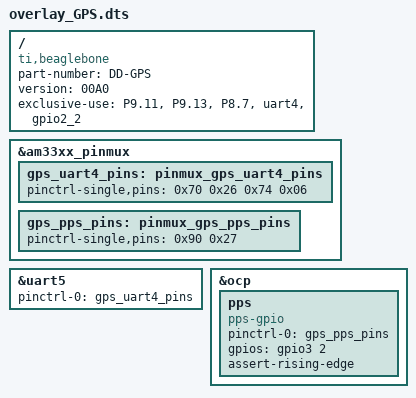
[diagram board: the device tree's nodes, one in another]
/*
 * Copyright (C) 2013 the8thlayerof.net
 *
 * GPS cape for UART4 on connector pins P9.11 P9.13 P8.7
 *
 * This program is free software; you can redistribute it and/or modify
 * it under the terms of the GNU General Public License version 2 as
 * published by the Free Software Foundation.
 */
/dts-v1/;
/plugin/;

/ {
        compatible = "ti,beaglebone", "ti,beaglebone-black";

        /* identification */
        part-number = "DD-GPS";
        version = "00A0";

        /* state the resources this cape uses */
        exclusive-use =
                /* the pin header uses */
                "P9.11",        /* uart4_rxd */
                "P9.13",        /* uart4_txd */
                "P8.7",        /* timer4/GPIO_66   */
                /* the hardware ip uses */
                "uart4", /* 0-based counting */
                "gpio2_2"; /* 0-based counting */

        fragment@0 {
                target = <&am33xx_pinmux>;
                __overlay__ {
                        gps_uart4_pins: pinmux_gps_uart4_pins {
                                pinctrl-single,pins = <
                                        0x70 0x26 /* P9.11 uart4_rxd MODE6 INPUT (RX) */
                                        0x74 0x06 /* P9.13 uart4_txd MODE6 OUTPUT (TX) */
                                >;
                        };

                        gps_pps_pins: pinmux_gps_pps_pins {
                                pinctrl-single,pins = <
                                      0x90 0x27 /* P8.7 gpio2_2 */
                                >;
                        };

                };
        };

        fragment@1 {
                target = <&uart5>;      /* 1-based counting */
                __overlay__ {
                        status = "okay";
                        pinctrl-names = "default";
                        pinctrl-0 = <&gps_uart4_pins>;
                };
        };

        fragment@2 {
                target = <&ocp>;

                __overlay__ {
                        pps {
                                compatible = "pps-gpio";
                                status = "okay";
                                pinctrl-names = "default";
                                pinctrl-0 = <&gps_pps_pins>;
                                gpios = <&gpio3 2 0 >; /* 1-based counting */
                                assert-rising-edge;
                        };
                };
        };
};
